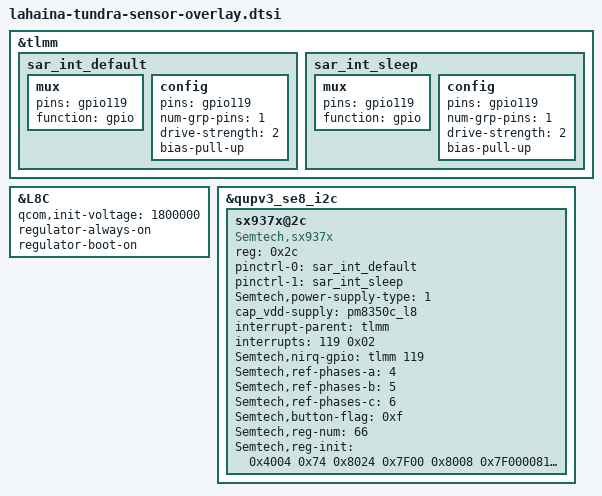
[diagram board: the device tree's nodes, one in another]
/* Copyright (c) 2019, The Linux Foundation. All rights reserved.
 *
 * This program is free software; you can redistribute it and/or modify
 * it under the terms of the GNU General Public License version 2 and
 * only version 2 as published by the Free Software Foundation.
 *
 * This program is distributed in the hope that it will be useful,
 * but WITHOUT ANY WARRANTY; without even the implied warranty of
 * MERCHANTABILITY or FITNESS FOR A PARTICULAR PURPOSE.  See the
 * GNU General Public License for more details.
 */

&tlmm {
	sar_int_default: sar_int_default {
			mux {
				pins = "gpio119";
				function =  "gpio";
			};
			config {
				pins = "gpio119";
				num-grp-pins = <1>;
				drive-strength = <2>;
				bias-pull-up;
			};
	};

	sar_int_sleep: sar_int_sleep {
			mux {
				pins = "gpio119";
				function =  "gpio";
			};
			config {
				pins = "gpio119";
				num-grp-pins = <1>;
				drive-strength = <2>;
				bias-pull-up;
			};
	};
};

&L8C {
	qcom,init-voltage = <1800000>;
	regulator-always-on;
	regulator-boot-on;
	status = "ok";
};

&qupv3_se8_i2c {
	status = "ok";
	sx937x@2c { /* SAR sensor */
		compatible = "Semtech,sx937x";
		reg = <0x2c>;
		pinctrl-names = "default","sleep";
		pinctrl-0 = <&sar_int_default>;
		pinctrl-1 = <&sar_int_sleep>;
		Semtech,power-supply-type = <1>;
		cap_vdd-supply = <&pm8350c_l8>;
		interrupt-parent = <&tlmm>;
		interrupts = <119 0x02>;
		interrupt-names = "sx937x_irq";
		Semtech,nirq-gpio= <&tlmm 119 0x02>;
		/*use PH4/5/6 as the reference sensor
		set it to 0xff if the ref-phases-x is not used*/
		Semtech,ref-phases-a = <4>;
		Semtech,ref-phases-b = <5>;
		Semtech,ref-phases-c = <6>;
		Semtech,button-flag = <0xf>;
		Semtech,reg-num = <66>;
		Semtech,reg-init = <
			0x4004 0x74
			0x8024 0x7F00
			0x8008 0x7F000081
			0x8020 0x32
			0x8028 0x87E
			0x8034 0x86E
			0x8040 0x87E
			0x804C 0x86E
			0x8058 0x87E
			0x8064 0x866
			0x8070 0x856
			0x807C 0x85E
			0x8030 0xFFF9FD
			0x803C 0xF7F9FF
			0x8048 0xBFF9FF
			0x8054 0xFFD9FF
			0x8060 0xFFF9EF
			0x806C 0xFFF97F
			0x8078 0xFEF9FF
			0x8084 0xBFF9FF
			0x8098 0x8040
			0x80B8 0x5A2A
			0x80D8 0x2828
			0x80F8 0x4747
			0x8118 0xFF
			0x8138 0xFF
			0x8158 0xFF
			0x8178 0xFF
			0x80A0 0x212100E1
			0x80C0 0x191900E3
			0x80E0 0x0
			0x8100 0x424200E3
			0x8120 0x0
			0x8140 0x0
			0x8160 0x0
			0x8180 0x0
			0x8188 0x8000014
			0x818C 0x0
			0x8190 0x8000016
			0x8194 0x0
			0x8090 0x3CDC5000
			0x80B0 0x3CDC5000
			0x80D0 0x3CDC5000
			0x80F0 0x3CDC5000
			0x8110 0x54AC5000
			0x8130 0x54AC5000
			0x8150 0x54AC5000
			0x8170 0x54AC5000
			0x8088 0x300000
			0x80A8 0x300000
			0x80C8 0x300000
			0x80E8 0x300000
			0x8108 0x600000
			0x8128 0x600000
			0x8148 0x600000
			0x8168 0x300000
			0x808C 0x60200030
			0x80AC 0x60200030
			0x80CC 0x60200030
			0x80EC 0x60200030
			0x810C 0x60200030
			0x812C 0x60200030
			0x814C 0x60200030
			0x816C 0x60200030
			0x8024 0x7F7F
			0x4280 0xF
		>;

		status = "ok";
	};
};
